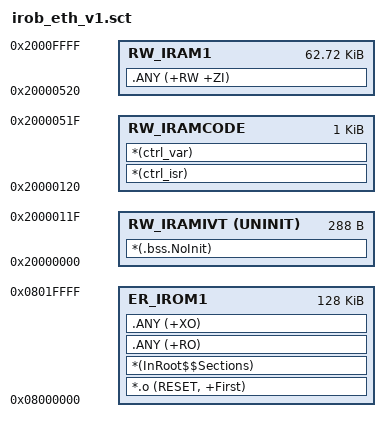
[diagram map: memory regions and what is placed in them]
; *************************************************************
; *** Scatter-Loading Description File generated by uVision ***
; *************************************************************

LR_IROM1 0x08000000 0x00020000  {    ; load region size_region
  ER_IROM1 0x08000000 0x00020000  {  ; load address = execution address
   *.o (RESET, +First)
   *(InRoot$$Sections)
   .ANY (+RO)
   .ANY (+XO)
  }
  RW_IRAMIVT  0x20000000 UNINIT 0x00000120 { ; IVT on SRAM
	*(.bss.NoInit)
  }
  
  RW_IRAMCODE 0x20000120 0x00000400 { ; Control loop ISR
	; app_controlloop.o
	*(ctrl_isr)
	*(ctrl_var)
  }
  
  RW_IRAM1 0x20000520 0x000FAE0  {  ; RW data
   .ANY (+RW +ZI)
  }
}

